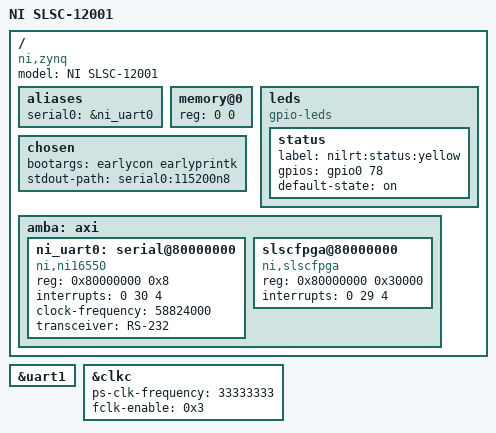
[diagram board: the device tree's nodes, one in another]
// SPDX-License-Identifier: GPL-2.0
/dts-v1/;
#include "zynq-7000.dtsi"
#include <dt-bindings/gpio/gpio.h>

/* NIDEVCODE 78AA */

/ {
	model = "NI SLSC-12001";
	compatible = "ni,zynq", "xlnx,zynq-7000";

	aliases {
		serial0 = &ni_uart0;
	};

	/* Populated by the bootloader */
	memory@0 {
		device_type = "memory";
		reg = <0 0>;
	};

	leds {
		compatible = "gpio-leds";

		status {
			label = "nilrt:status:yellow";
			gpios = <&gpio0 78 GPIO_ACTIVE_HIGH>;
			default-state = "on";
		};
	};

	chosen {
		bootargs = "earlycon earlyprintk";
		stdout-path = "serial0:115200n8";
	};

	amba: axi {
		ni_uart0: serial@80000000 {
			device_type = "serial";
			compatible = "ni,ni16550";
			status = "disabled";
			reg = <0x80000000 0x8>;
			interrupts = <0 30 4>;
			clock-frequency = <58824000>;
			/* Populated by the bootloader */
			/* current-speed = <0>; */
		};

		slscfpga@80000000 {
		   compatible = "ni,slscfpga";
		   reg = <0x80000000 0x30000>;
		   interrupts = <0 29 4>;
		};
	};
};

&ni_uart0 {
		status = "okay";
		transceiver = "RS-232";
};

&uart1 {
		status = "okay";
};

&clkc {
		/* Enable fclk0 for eth0 and eth1, fclk1 for serial. */
		ps-clk-frequency = <33333333>;
		fclk-enable = <0x3>;
};
